VERSION "100"

NS_ :

BS_:

BU_: C185

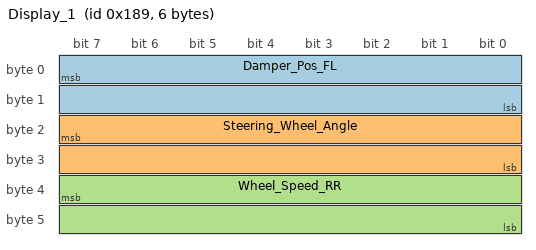
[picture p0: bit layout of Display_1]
BO_ 393 Display_1: 6 C185
 SG_ Damper_Pos_FL : 7|16@0- (1E-05,0) [-10000|10000] "m"  Vector__XXX
 SG_ Steering_Wheel_Angle : 23|16@0- (0.1,0) [-3600|3600] "deg"  Vector__XXX
 SG_ Wheel_Speed_RR : 39|16@0- (0.1,0) [0|3000] "km/h"  Vector__XXX

BO_ 394 Display_2: 4 C185
 SG_ Coolant_Temperature : 7|16@0- (0.1,0) [0|0] "C"  Vector__XXX
 SG_ Brake_Pressure_Front : 23|16@0- (1,0) [0|0] "kPa"  Vector__XXX

BO_ 395 Alarm_Message: 8 C185
 SG_ Alarm_Message : 7|64@0+ (0,0) [0|0] ""  Vector__XXX

BO_ 396 Alarm_Value: 8 C185
 SG_ Alarm_Value : 7|64@0+ (0,0) [0|0] ""  Vector__XXX

BO_ 397 Alarm_Status: 2 C185
 SG_ Alarm_Active : 7|8@0+ (0,0) [0|0] ""  Vector__XXX
 SG_ Alarm_Flash : 15|8@0+ (0,0) [0|0] ""  Vector__XXX

BO_ 392 CRC32: 4 C185
 SG_ CRC32 : 7|32@0+ (1,0) [0|0] ""  Vector__XXX

BA_DEF_  "MoTeC_CRC" INT 0 0;
BA_DEF_ SG_  "MoTeC_Type" ENUM  "Number","Compound_String";
BA_DEF_ SG_  "MoTeC_Usage" ENUM  "General","CRC32","Alarm_Message","Alarm_Value","Alarm_Active_State","Alarm_Flash_State";
BA_DEF_ SG_  "MoTeC_Channel" STRING ;
BA_DEF_ BO_  "GenMsgCycleTime" INT 0 0;
BA_DEF_DEF_  "MoTeC_CRC" -385032153;
BA_DEF_DEF_  "MoTeC_Type" "Number";
BA_DEF_DEF_  "MoTeC_Usage" "General";
BA_DEF_DEF_  "MoTeC_Channel" "";
BA_DEF_DEF_  "GenMsgCycleTime" 50;
BA_ "GenMsgCycleTime" BO_ 394 100;
BA_ "GenMsgCycleTime" BO_ 392 1000;
BA_ "MoTeC_Channel" SG_ 393 Damper_Pos_FL "Damper Pos FL";
BA_ "MoTeC_Channel" SG_ 393 Steering_Wheel_Angle "Steering Wheel Angle";
BA_ "MoTeC_Channel" SG_ 393 Wheel_Speed_RR "Wheel Speed RR";
BA_ "MoTeC_Channel" SG_ 394 Coolant_Temperature "Coolant Temperature";
BA_ "MoTeC_Channel" SG_ 394 Brake_Pressure_Front "Brake Pressure Front";
BA_ "MoTeC_Type" SG_ 395 Alarm_Message 1;
BA_ "MoTeC_Usage" SG_ 395 Alarm_Message 2;
BA_ "MoTeC_Type" SG_ 396 Alarm_Value 1;
BA_ "MoTeC_Usage" SG_ 396 Alarm_Value 3;
BA_ "MoTeC_Usage" SG_ 397 Alarm_Active 4;
BA_ "MoTeC_Usage" SG_ 397 Alarm_Flash 5;
BA_ "MoTeC_Usage" SG_ 392 CRC32 1;
